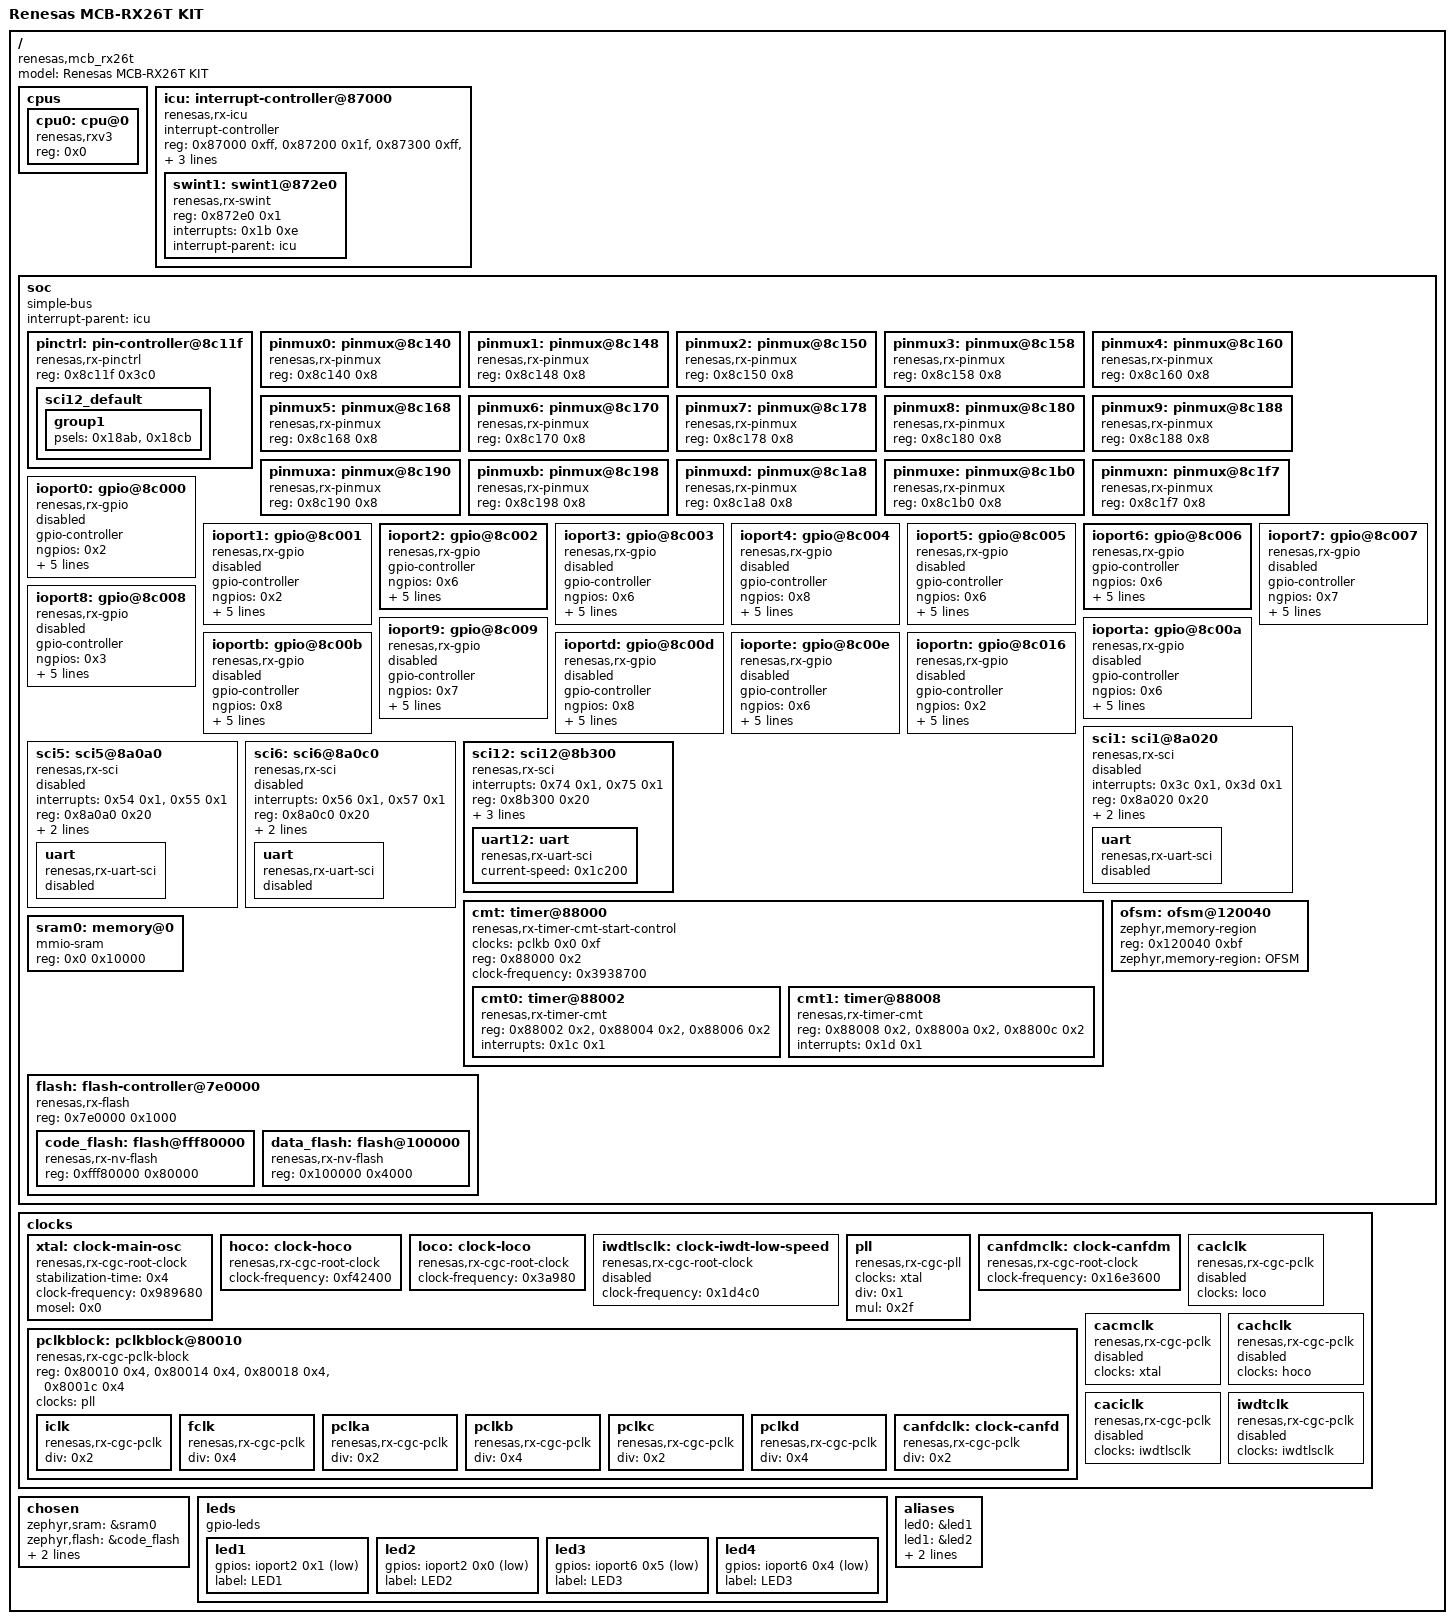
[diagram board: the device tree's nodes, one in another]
/dts-v1/;

/* node '/' defined in zephyr/dts/rx/renesas/rx26t-common.dtsi:15 */
/ {
	#address-cells = < 0x1 >;         /* in zephyr/dts/rx/renesas/rx26t-common.dtsi:16 */
	#size-cells = < 0x1 >;            /* in zephyr/dts/rx/renesas/rx26t-common.dtsi:17 */
	model = "Renesas MCB-RX26T KIT";  /* in zephyr/boards/renesas/mcb_rx26t/mcb_rx26t.dts:14 */
	compatible = "renesas,mcb_rx26t"; /* in zephyr/boards/renesas/mcb_rx26t/mcb_rx26t.dts:15 */

	/* node '/cpus' defined in zephyr/dts/rx/renesas/rx26t-common.dtsi:18 */
	cpus {
		#address-cells = < 0x1 >; /* in zephyr/dts/rx/renesas/rx26t-common.dtsi:19 */
		#size-cells = < 0x0 >;    /* in zephyr/dts/rx/renesas/rx26t-common.dtsi:20 */

		/* node '/cpus/cpu@0' defined in zephyr/dts/rx/renesas/rx26t-common.dtsi:22 */
		cpu0: cpu@0 {
			compatible = "renesas,rxv3"; /* in zephyr/dts/rx/renesas/rx26t-common.dtsi:23 */
			device_type = "cpu";         /* in zephyr/dts/rx/renesas/rx26t-common.dtsi:24 */
			reg = < 0x0 >;               /* in zephyr/dts/rx/renesas/rx26t-common.dtsi:25 */
			status = "okay";             /* in zephyr/dts/rx/renesas/rx26t-common.dtsi:26 */
		};
	};

	/* node '/interrupt-controller@87000' defined in zephyr/dts/rx/renesas/rx26t-common.dtsi:30 */
	icu: interrupt-controller@87000 {
		#interrupt-cells = < 0x2 >;    /* in zephyr/dts/rx/renesas/rx26t-common.dtsi:31 */
		#address-cells = < 0x1 >;      /* in zephyr/dts/rx/renesas/rx26t-common.dtsi:32 */
		#size-cells = < 0x1 >;         /* in zephyr/dts/rx/renesas/rx26t-common.dtsi:33 */
		compatible = "renesas,rx-icu"; /* in zephyr/dts/rx/renesas/rx26t-common.dtsi:34 */
		interrupt-controller;          /* in zephyr/dts/rx/renesas/rx26t-common.dtsi:35 */
		reg = < 0x87000 0xff >,
		      < 0x87200 0x1f >,
		      < 0x87300 0xff >,
		      < 0x872f0 0x2 >,
		      < 0x87500 0xf >,
		      < 0x87510 0x1 >,
		      < 0x87514 0x1 >,
		      < 0x87580 0x1 >,
		      < 0x87581 0x1 >,
		      < 0x87582 0x1 >;         /* in zephyr/dts/rx/renesas/rx26t-common.dtsi:36 */
		reg-names = "IR",
		            "IER",
		            "IPR",
		            "FIR",
		            "IRQCR",
		            "IRQFLTE",
		            "IRQFLTC0",
		            "NMISR",
		            "NMIER",
		            "NMICLR";          /* in zephyr/dts/rx/renesas/rx26t-common.dtsi:46 */
		phandle = < 0x1 >;             /* in zephyr/dts/rx/renesas/rx26t-common.dtsi:53 */

		/* node '/interrupt-controller@87000/swint1@872e0' defined in zephyr/dts/rx/renesas/rx26t-common.dtsi:49 */
		swint1: swint1@872e0 {
			compatible = "renesas,rx-swint"; /* in zephyr/dts/rx/renesas/rx26t-common.dtsi:50 */
			reg = < 0x872e0 0x1 >;           /* in zephyr/dts/rx/renesas/rx26t-common.dtsi:51 */
			interrupts = < 0x1b 0xe >;       /* in zephyr/dts/rx/renesas/rx26t-common.dtsi:52 */
			interrupt-parent = < &icu >;     /* in zephyr/dts/rx/renesas/rx26t-common.dtsi:53 */
			status = "okay";                 /* in zephyr/dts/rx/renesas/rx26t-common.dtsi:54 */
		};
	};

	/* node '/soc' defined in zephyr/dts/rx/renesas/rx26t-common.dtsi:58 */
	soc {
		#address-cells = < 0x1 >;    /* in zephyr/dts/rx/renesas/rx26t-common.dtsi:59 */
		#size-cells = < 0x1 >;       /* in zephyr/dts/rx/renesas/rx26t-common.dtsi:60 */
		device_type = "soc";         /* in zephyr/dts/rx/renesas/rx26t-common.dtsi:61 */
		compatible = "simple-bus";   /* in zephyr/dts/rx/renesas/rx26t-common.dtsi:62 */
		interrupt-parent = < &icu >; /* in zephyr/dts/rx/renesas/rx26t-common.dtsi:63 */

		/* node '/soc/pin-controller@8c11f' defined in zephyr/dts/rx/renesas/rx26t-common.dtsi:65 */
		pinctrl: pin-controller@8c11f {
			compatible = "renesas,rx-pinctrl"; /* in zephyr/dts/rx/renesas/rx26t-common.dtsi:66 */
			reg = < 0x8c11f 0x3c0 >;           /* in zephyr/dts/rx/renesas/rx26t-common.dtsi:67 */
			status = "okay";                   /* in zephyr/dts/rx/renesas/rx26t-common.dtsi:68 */

			/* node '/soc/pin-controller@8c11f/sci12_default' defined in zephyr/boards/renesas/mcb_rx26t/mcb_rx26t-pinctrl.dtsi:8 */
			sci12_default: sci12_default {
				phandle = < 0x11 >; /* in zephyr/boards/renesas/mcb_rx26t/mcb_rx26t.dts:83 */

				/* node '/soc/pin-controller@8c11f/sci12_default/group1' defined in zephyr/boards/renesas/mcb_rx26t/mcb_rx26t-pinctrl.dtsi:9 */
				group1 {
					psels = < 0x18ab >,
					        < 0x18cb >; /* in zephyr/boards/renesas/mcb_rx26t/mcb_rx26t-pinctrl.dtsi:10 */
				};
			};
		};

		/* node '/soc/pinmux@8c140' defined in zephyr/dts/rx/renesas/rx26t-common.dtsi:71 */
		pinmux0: pinmux@8c140 {
			compatible = "renesas,rx-pinmux"; /* in zephyr/dts/rx/renesas/rx26t-common.dtsi:72 */
			#pinmux-cells = < 0x2 >;          /* in zephyr/dts/rx/renesas/rx26t-common.dtsi:73 */
			reg = < 0x8c140 0x8 >;            /* in zephyr/dts/rx/renesas/rx26t-common.dtsi:74 */
			status = "okay";                  /* in zephyr/dts/rx/renesas/rx26t-common.dtsi:75 */
			phandle = < 0x2 >;                /* in zephyr/dts/rx/renesas/rx26t-common.dtsi:190 */
		};

		/* node '/soc/pinmux@8c148' defined in zephyr/dts/rx/renesas/rx26t-common.dtsi:78 */
		pinmux1: pinmux@8c148 {
			compatible = "renesas,rx-pinmux"; /* in zephyr/dts/rx/renesas/rx26t-common.dtsi:79 */
			#pinmux-cells = < 0x2 >;          /* in zephyr/dts/rx/renesas/rx26t-common.dtsi:80 */
			reg = < 0x8c148 0x8 >;            /* in zephyr/dts/rx/renesas/rx26t-common.dtsi:81 */
			status = "okay";                  /* in zephyr/dts/rx/renesas/rx26t-common.dtsi:82 */
			phandle = < 0x3 >;                /* in zephyr/dts/rx/renesas/rx26t-common.dtsi:208 */
		};

		/* node '/soc/pinmux@8c150' defined in zephyr/dts/rx/renesas/rx26t-common.dtsi:85 */
		pinmux2: pinmux@8c150 {
			compatible = "renesas,rx-pinmux"; /* in zephyr/dts/rx/renesas/rx26t-common.dtsi:86 */
			#pinmux-cells = < 0x2 >;          /* in zephyr/dts/rx/renesas/rx26t-common.dtsi:87 */
			reg = < 0x8c150 0x8 >;            /* in zephyr/dts/rx/renesas/rx26t-common.dtsi:88 */
			status = "okay";                  /* in zephyr/dts/rx/renesas/rx26t-common.dtsi:89 */
			phandle = < 0x4 >;                /* in zephyr/dts/rx/renesas/rx26t-common.dtsi:227 */
		};

		/* node '/soc/pinmux@8c158' defined in zephyr/dts/rx/renesas/rx26t-common.dtsi:92 */
		pinmux3: pinmux@8c158 {
			compatible = "renesas,rx-pinmux"; /* in zephyr/dts/rx/renesas/rx26t-common.dtsi:93 */
			#pinmux-cells = < 0x2 >;          /* in zephyr/dts/rx/renesas/rx26t-common.dtsi:94 */
			reg = < 0x8c158 0x8 >;            /* in zephyr/dts/rx/renesas/rx26t-common.dtsi:95 */
			status = "okay";                  /* in zephyr/dts/rx/renesas/rx26t-common.dtsi:96 */
			phandle = < 0x5 >;                /* in zephyr/dts/rx/renesas/rx26t-common.dtsi:246 */
		};

		/* node '/soc/pinmux@8c160' defined in zephyr/dts/rx/renesas/rx26t-common.dtsi:99 */
		pinmux4: pinmux@8c160 {
			compatible = "renesas,rx-pinmux"; /* in zephyr/dts/rx/renesas/rx26t-common.dtsi:100 */
			#pinmux-cells = < 0x2 >;          /* in zephyr/dts/rx/renesas/rx26t-common.dtsi:101 */
			reg = < 0x8c160 0x8 >;            /* in zephyr/dts/rx/renesas/rx26t-common.dtsi:102 */
			status = "okay";                  /* in zephyr/dts/rx/renesas/rx26t-common.dtsi:103 */
			phandle = < 0x6 >;                /* in zephyr/dts/rx/renesas/rx26t-common.dtsi:264 */
		};

		/* node '/soc/pinmux@8c168' defined in zephyr/dts/rx/renesas/rx26t-common.dtsi:106 */
		pinmux5: pinmux@8c168 {
			compatible = "renesas,rx-pinmux"; /* in zephyr/dts/rx/renesas/rx26t-common.dtsi:107 */
			#pinmux-cells = < 0x2 >;          /* in zephyr/dts/rx/renesas/rx26t-common.dtsi:108 */
			reg = < 0x8c168 0x8 >;            /* in zephyr/dts/rx/renesas/rx26t-common.dtsi:109 */
			status = "okay";                  /* in zephyr/dts/rx/renesas/rx26t-common.dtsi:110 */
			phandle = < 0x7 >;                /* in zephyr/dts/rx/renesas/rx26t-common.dtsi:282 */
		};

		/* node '/soc/pinmux@8c170' defined in zephyr/dts/rx/renesas/rx26t-common.dtsi:113 */
		pinmux6: pinmux@8c170 {
			compatible = "renesas,rx-pinmux"; /* in zephyr/dts/rx/renesas/rx26t-common.dtsi:114 */
			#pinmux-cells = < 0x2 >;          /* in zephyr/dts/rx/renesas/rx26t-common.dtsi:115 */
			reg = < 0x8c170 0x8 >;            /* in zephyr/dts/rx/renesas/rx26t-common.dtsi:116 */
			status = "okay";                  /* in zephyr/dts/rx/renesas/rx26t-common.dtsi:117 */
		};

		/* node '/soc/pinmux@8c178' defined in zephyr/dts/rx/renesas/rx26t-common.dtsi:120 */
		pinmux7: pinmux@8c178 {
			compatible = "renesas,rx-pinmux"; /* in zephyr/dts/rx/renesas/rx26t-common.dtsi:121 */
			#pinmux-cells = < 0x2 >;          /* in zephyr/dts/rx/renesas/rx26t-common.dtsi:122 */
			reg = < 0x8c178 0x8 >;            /* in zephyr/dts/rx/renesas/rx26t-common.dtsi:123 */
			status = "okay";                  /* in zephyr/dts/rx/renesas/rx26t-common.dtsi:124 */
			phandle = < 0x8 >;                /* in zephyr/dts/rx/renesas/rx26t-common.dtsi:321 */
		};

		/* node '/soc/pinmux@8c180' defined in zephyr/dts/rx/renesas/rx26t-common.dtsi:127 */
		pinmux8: pinmux@8c180 {
			compatible = "renesas,rx-pinmux"; /* in zephyr/dts/rx/renesas/rx26t-common.dtsi:128 */
			#pinmux-cells = < 0x2 >;          /* in zephyr/dts/rx/renesas/rx26t-common.dtsi:129 */
			reg = < 0x8c180 0x8 >;            /* in zephyr/dts/rx/renesas/rx26t-common.dtsi:130 */
			status = "okay";                  /* in zephyr/dts/rx/renesas/rx26t-common.dtsi:131 */
			phandle = < 0x9 >;                /* in zephyr/dts/rx/renesas/rx26t-common.dtsi:341 */
		};

		/* node '/soc/pinmux@8c188' defined in zephyr/dts/rx/renesas/rx26t-common.dtsi:134 */
		pinmux9: pinmux@8c188 {
			compatible = "renesas,rx-pinmux"; /* in zephyr/dts/rx/renesas/rx26t-common.dtsi:135 */
			#pinmux-cells = < 0x2 >;          /* in zephyr/dts/rx/renesas/rx26t-common.dtsi:136 */
			reg = < 0x8c188 0x8 >;            /* in zephyr/dts/rx/renesas/rx26t-common.dtsi:137 */
			status = "okay";                  /* in zephyr/dts/rx/renesas/rx26t-common.dtsi:138 */
			phandle = < 0xa >;                /* in zephyr/dts/rx/renesas/rx26t-common.dtsi:362 */
		};

		/* node '/soc/pinmux@8c190' defined in zephyr/dts/rx/renesas/rx26t-common.dtsi:141 */
		pinmuxa: pinmux@8c190 {
			compatible = "renesas,rx-pinmux"; /* in zephyr/dts/rx/renesas/rx26t-common.dtsi:142 */
			#pinmux-cells = < 0x2 >;          /* in zephyr/dts/rx/renesas/rx26t-common.dtsi:143 */
			reg = < 0x8c190 0x8 >;            /* in zephyr/dts/rx/renesas/rx26t-common.dtsi:144 */
			status = "okay";                  /* in zephyr/dts/rx/renesas/rx26t-common.dtsi:145 */
			phandle = < 0xb >;                /* in zephyr/dts/rx/renesas/rx26t-common.dtsi:382 */
		};

		/* node '/soc/pinmux@8c198' defined in zephyr/dts/rx/renesas/rx26t-common.dtsi:148 */
		pinmuxb: pinmux@8c198 {
			compatible = "renesas,rx-pinmux"; /* in zephyr/dts/rx/renesas/rx26t-common.dtsi:149 */
			#pinmux-cells = < 0x2 >;          /* in zephyr/dts/rx/renesas/rx26t-common.dtsi:150 */
			reg = < 0x8c198 0x8 >;            /* in zephyr/dts/rx/renesas/rx26t-common.dtsi:151 */
			status = "okay";                  /* in zephyr/dts/rx/renesas/rx26t-common.dtsi:152 */
			phandle = < 0xc >;                /* in zephyr/dts/rx/renesas/rx26t-common.dtsi:403 */
		};

		/* node '/soc/pinmux@8c1a8' defined in zephyr/dts/rx/renesas/rx26t-common.dtsi:155 */
		pinmuxd: pinmux@8c1a8 {
			compatible = "renesas,rx-pinmux"; /* in zephyr/dts/rx/renesas/rx26t-common.dtsi:156 */
			#pinmux-cells = < 0x2 >;          /* in zephyr/dts/rx/renesas/rx26t-common.dtsi:157 */
			reg = < 0x8c1a8 0x8 >;            /* in zephyr/dts/rx/renesas/rx26t-common.dtsi:158 */
			status = "okay";                  /* in zephyr/dts/rx/renesas/rx26t-common.dtsi:159 */
			phandle = < 0xd >;                /* in zephyr/dts/rx/renesas/rx26t-common.dtsi:424 */
		};

		/* node '/soc/pinmux@8c1b0' defined in zephyr/dts/rx/renesas/rx26t-common.dtsi:162 */
		pinmuxe: pinmux@8c1b0 {
			compatible = "renesas,rx-pinmux"; /* in zephyr/dts/rx/renesas/rx26t-common.dtsi:163 */
			#pinmux-cells = < 0x2 >;          /* in zephyr/dts/rx/renesas/rx26t-common.dtsi:164 */
			reg = < 0x8c1b0 0x8 >;            /* in zephyr/dts/rx/renesas/rx26t-common.dtsi:165 */
			status = "okay";                  /* in zephyr/dts/rx/renesas/rx26t-common.dtsi:166 */
			phandle = < 0xe >;                /* in zephyr/dts/rx/renesas/rx26t-common.dtsi:443 */
		};

		/* node '/soc/pinmux@8c1f7' defined in zephyr/dts/rx/renesas/rx26t-common.dtsi:169 */
		pinmuxn: pinmux@8c1f7 {
			compatible = "renesas,rx-pinmux"; /* in zephyr/dts/rx/renesas/rx26t-common.dtsi:170 */
			#pinmux-cells = < 0x2 >;          /* in zephyr/dts/rx/renesas/rx26t-common.dtsi:171 */
			reg = < 0x8c1f7 0x8 >;            /* in zephyr/dts/rx/renesas/rx26t-common.dtsi:172 */
			status = "okay";                  /* in zephyr/dts/rx/renesas/rx26t-common.dtsi:173 */
			phandle = < 0xf >;                /* in zephyr/dts/rx/renesas/rx26t-common.dtsi:461 */
		};

		/* node '/soc/gpio@8c000' defined in zephyr/dts/rx/renesas/rx26t-common.dtsi:176 */
		ioport0: gpio@8c000 {
			compatible = "renesas,rx-gpio"; /* in zephyr/dts/rx/renesas/rx26t-common.dtsi:177 */
			gpio-controller;                /* in zephyr/dts/rx/renesas/rx26t-common.dtsi:178 */
			#gpio-cells = < 0x2 >;          /* in zephyr/dts/rx/renesas/rx26t-common.dtsi:179 */
			ngpios = < 0x2 >;               /* in zephyr/dts/rx/renesas/rx26t-common.dtsi:180 */
			port = < 0x0 >;                 /* in zephyr/dts/rx/renesas/rx26t-common.dtsi:181 */
			reg = < 0x8c000 0x1 >,
			      < 0x8c020 0x1 >,
			      < 0x8c040 0x1 >,
			      < 0x8c060 0x1 >,
			      < 0x8c080 0x1 >,
			      < 0x8c0c0 0x1 >,
			      < 0x8c0e0 0x1 >;          /* in zephyr/dts/rx/renesas/rx26t-common.dtsi:182 */
			reg-names = "PDR",
			            "PODR",
			            "PIDR",
			            "PMR",
			            "ODR0",
			            "PCR",
			            "DSCR";             /* in zephyr/dts/rx/renesas/rx26t-common.dtsi:189 */
			pinmux = < &pinmux0 >;          /* in zephyr/dts/rx/renesas/rx26t-common.dtsi:190 */
			status = "disabled";            /* in zephyr/dts/rx/renesas/rx26t-common.dtsi:191 */
		};

		/* node '/soc/gpio@8c001' defined in zephyr/dts/rx/renesas/rx26t-common.dtsi:194 */
		ioport1: gpio@8c001 {
			compatible = "renesas,rx-gpio"; /* in zephyr/dts/rx/renesas/rx26t-common.dtsi:195 */
			gpio-controller;                /* in zephyr/dts/rx/renesas/rx26t-common.dtsi:196 */
			#gpio-cells = < 0x2 >;          /* in zephyr/dts/rx/renesas/rx26t-common.dtsi:197 */
			ngpios = < 0x2 >;               /* in zephyr/dts/rx/renesas/rx26t-common.dtsi:198 */
			port = < 0x1 >;                 /* in zephyr/dts/rx/renesas/rx26t-common.dtsi:199 */
			reg = < 0x8c001 0x1 >,
			      < 0x8c021 0x1 >,
			      < 0x8c041 0x1 >,
			      < 0x8c061 0x1 >,
			      < 0x8c082 0x1 >,
			      < 0x8c0c1 0x1 >,
			      < 0x8c0e1 0x1 >;          /* in zephyr/dts/rx/renesas/rx26t-common.dtsi:200 */
			reg-names = "PDR",
			            "PODR",
			            "PIDR",
			            "PMR",
			            "ODR0",
			            "PCR",
			            "DSCR";             /* in zephyr/dts/rx/renesas/rx26t-common.dtsi:207 */
			pinmux = < &pinmux1 >;          /* in zephyr/dts/rx/renesas/rx26t-common.dtsi:208 */
			status = "disabled";            /* in zephyr/dts/rx/renesas/rx26t-common.dtsi:209 */
		};

		/* node '/soc/gpio@8c002' defined in zephyr/dts/rx/renesas/rx26t-common.dtsi:212 */
		ioport2: gpio@8c002 {
			compatible = "renesas,rx-gpio"; /* in zephyr/dts/rx/renesas/rx26t-common.dtsi:213 */
			gpio-controller;                /* in zephyr/dts/rx/renesas/rx26t-common.dtsi:214 */
			#gpio-cells = < 0x2 >;          /* in zephyr/dts/rx/renesas/rx26t-common.dtsi:215 */
			ngpios = < 0x6 >;               /* in zephyr/dts/rx/renesas/rx26t-common.dtsi:216 */
			port = < 0x2 >;                 /* in zephyr/dts/rx/renesas/rx26t-common.dtsi:217 */
			reg = < 0x8c002 0x1 >,
			      < 0x8c022 0x1 >,
			      < 0x8c042 0x1 >,
			      < 0x8c062 0x1 >,
			      < 0x8c084 0x1 >,
			      < 0x8c085 0x1 >,
			      < 0x8c0c2 0x1 >,
			      < 0x8c0e2 0x1 >;          /* in zephyr/dts/rx/renesas/rx26t-common.dtsi:218 */
			reg-names = "PDR",
			            "PODR",
			            "PIDR",
			            "PMR",
			            "ODR0",
			            "ODR1",
			            "PCR",
			            "DSCR";             /* in zephyr/dts/rx/renesas/rx26t-common.dtsi:226 */
			pinmux = < &pinmux2 >;          /* in zephyr/dts/rx/renesas/rx26t-common.dtsi:227 */
			status = "okay";                /* in zephyr/boards/renesas/mcb_rx26t/mcb_rx26t.dts:75 */
			phandle = < 0x17 >;             /* in zephyr/boards/renesas/mcb_rx26t/mcb_rx26t.dts:28 */
		};

		/* node '/soc/gpio@8c003' defined in zephyr/dts/rx/renesas/rx26t-common.dtsi:231 */
		ioport3: gpio@8c003 {
			compatible = "renesas,rx-gpio"; /* in zephyr/dts/rx/renesas/rx26t-common.dtsi:232 */
			gpio-controller;                /* in zephyr/dts/rx/renesas/rx26t-common.dtsi:233 */
			#gpio-cells = < 0x2 >;          /* in zephyr/dts/rx/renesas/rx26t-common.dtsi:234 */
			ngpios = < 0x6 >;               /* in zephyr/dts/rx/renesas/rx26t-common.dtsi:235 */
			port = < 0x3 >;                 /* in zephyr/dts/rx/renesas/rx26t-common.dtsi:236 */
			reg = < 0x8c003 0x1 >,
			      < 0x8c023 0x1 >,
			      < 0x8c043 0x1 >,
			      < 0x8c063 0x1 >,
			      < 0x8c086 0x1 >,
			      < 0x8c087 0x1 >,
			      < 0x8c0c3 0x1 >,
			      < 0x8c0e3 0x1 >;          /* in zephyr/dts/rx/renesas/rx26t-common.dtsi:237 */
			reg-names = "PDR",
			            "PODR",
			            "PIDR",
			            "PMR",
			            "ODR0",
			            "ODR1",
			            "PCR",
			            "DSCR";             /* in zephyr/dts/rx/renesas/rx26t-common.dtsi:245 */
			pinmux = < &pinmux3 >;          /* in zephyr/dts/rx/renesas/rx26t-common.dtsi:246 */
			status = "disabled";            /* in zephyr/dts/rx/renesas/rx26t-common.dtsi:247 */
		};

		/* node '/soc/gpio@8c004' defined in zephyr/dts/rx/renesas/rx26t-common.dtsi:250 */
		ioport4: gpio@8c004 {
			compatible = "renesas,rx-gpio"; /* in zephyr/dts/rx/renesas/rx26t-common.dtsi:251 */
			gpio-controller;                /* in zephyr/dts/rx/renesas/rx26t-common.dtsi:252 */
			#gpio-cells = < 0x2 >;          /* in zephyr/dts/rx/renesas/rx26t-common.dtsi:253 */
			ngpios = < 0x8 >;               /* in zephyr/dts/rx/renesas/rx26t-common.dtsi:254 */
			port = < 0x4 >;                 /* in zephyr/dts/rx/renesas/rx26t-common.dtsi:255 */
			reg = < 0x8c004 0x1 >,
			      < 0x8c024 0x1 >,
			      < 0x8c044 0x1 >,
			      < 0x8c064 0x1 >,
			      < 0x8c088 0x1 >,
			      < 0x8c089 0x1 >,
			      < 0x8c0c4 0x1 >;          /* in zephyr/dts/rx/renesas/rx26t-common.dtsi:256 */
			reg-names = "PDR",
			            "PODR",
			            "PIDR",
			            "PMR",
			            "ODR0",
			            "ODR1",
			            "PCR";              /* in zephyr/dts/rx/renesas/rx26t-common.dtsi:263 */
			pinmux = < &pinmux4 >;          /* in zephyr/dts/rx/renesas/rx26t-common.dtsi:264 */
			status = "disabled";            /* in zephyr/dts/rx/renesas/rx26t-common.dtsi:265 */
		};

		/* node '/soc/gpio@8c005' defined in zephyr/dts/rx/renesas/rx26t-common.dtsi:268 */
		ioport5: gpio@8c005 {
			compatible = "renesas,rx-gpio"; /* in zephyr/dts/rx/renesas/rx26t-common.dtsi:269 */
			gpio-controller;                /* in zephyr/dts/rx/renesas/rx26t-common.dtsi:270 */
			#gpio-cells = < 0x2 >;          /* in zephyr/dts/rx/renesas/rx26t-common.dtsi:271 */
			ngpios = < 0x6 >;               /* in zephyr/dts/rx/renesas/rx26t-common.dtsi:272 */
			port = < 0x5 >;                 /* in zephyr/dts/rx/renesas/rx26t-common.dtsi:273 */
			reg = < 0x8c005 0x1 >,
			      < 0x8c025 0x1 >,
			      < 0x8c045 0x1 >,
			      < 0x8c065 0x1 >,
			      < 0x8c08a 0x1 >,
			      < 0x8c08b 0x1 >,
			      < 0x8c0c5 0x1 >;          /* in zephyr/dts/rx/renesas/rx26t-common.dtsi:274 */
			reg-names = "PDR",
			            "PODR",
			            "PIDR",
			            "PMR",
			            "ODR0",
			            "ODR1",
			            "PCR";              /* in zephyr/dts/rx/renesas/rx26t-common.dtsi:281 */
			pinmux = < &pinmux5 >;          /* in zephyr/dts/rx/renesas/rx26t-common.dtsi:282 */
			status = "disabled";            /* in zephyr/dts/rx/renesas/rx26t-common.dtsi:283 */
		};

		/* node '/soc/gpio@8c006' defined in zephyr/dts/rx/renesas/rx26t-common.dtsi:286 */
		ioport6: gpio@8c006 {
			compatible = "renesas,rx-gpio"; /* in zephyr/dts/rx/renesas/rx26t-common.dtsi:287 */
			gpio-controller;                /* in zephyr/dts/rx/renesas/rx26t-common.dtsi:288 */
			#gpio-cells = < 0x2 >;          /* in zephyr/dts/rx/renesas/rx26t-common.dtsi:289 */
			ngpios = < 0x6 >;               /* in zephyr/dts/rx/renesas/rx26t-common.dtsi:290 */
			port = < 0x6 >;                 /* in zephyr/dts/rx/renesas/rx26t-common.dtsi:291 */
			reg = < 0x8c006 0x1 >,
			      < 0x8c026 0x1 >,
			      < 0x8c046 0x1 >,
			      < 0x8c066 0x1 >,
			      < 0x8c08c 0x1 >,
			      < 0x8c08d 0x1 >,
			      < 0x8c0c6 0x1 >;          /* in zephyr/dts/rx/renesas/rx26t-common.dtsi:292 */
			reg-names = "PDR",
			            "PODR",
			            "PIDR",
			            "PMR",
			            "ODR0",
			            "ODR1",
			            "PCR";              /* in zephyr/dts/rx/renesas/rx26t-common.dtsi:299 */
			pinmux = < &pinmux5 >;          /* in zephyr/dts/rx/renesas/rx26t-common.dtsi:300 */
			status = "okay";                /* in zephyr/boards/renesas/mcb_rx26t/mcb_rx26t.dts:79 */
			phandle = < 0x18 >;             /* in zephyr/boards/renesas/mcb_rx26t/mcb_rx26t.dts:38 */
		};

		/* node '/soc/gpio@8c007' defined in zephyr/dts/rx/renesas/rx26t-common.dtsi:304 */
		ioport7: gpio@8c007 {
			compatible = "renesas,rx-gpio"; /* in zephyr/dts/rx/renesas/rx26t-common.dtsi:305 */
			gpio-controller;                /* in zephyr/dts/rx/renesas/rx26t-common.dtsi:306 */
			#gpio-cells = < 0x2 >;          /* in zephyr/dts/rx/renesas/rx26t-common.dtsi:307 */
			ngpios = < 0x7 >;               /* in zephyr/dts/rx/renesas/rx26t-common.dtsi:308 */
			port = < 0x7 >;                 /* in zephyr/dts/rx/renesas/rx26t-common.dtsi:309 */
			reg = < 0x8c007 0x1 >,
			      < 0x8c027 0x1 >,
			      < 0x8c047 0x1 >,
			      < 0x8c067 0x1 >,
			      < 0x8c08e 0x1 >,
			      < 0x8c08f 0x1 >,
			      < 0x8c0c7 0x1 >,
			      < 0x8c0e7 0x1 >,
			      < 0x8c12f 0x1 >;          /* in zephyr/dts/rx/renesas/rx26t-common.dtsi:310 */
			reg-names = "PDR",
			            "PODR",
			            "PIDR",
			            "PMR",
			            "ODR0",
			            "ODR1",
			            "PCR",
			            "DSCR",
			            "DSCR2";            /* in zephyr/dts/rx/renesas/rx26t-common.dtsi:319 */
			pinmux = < &pinmux7 >;          /* in zephyr/dts/rx/renesas/rx26t-common.dtsi:321 */
			status = "disabled";            /* in zephyr/dts/rx/renesas/rx26t-common.dtsi:322 */
		};

		/* node '/soc/gpio@8c008' defined in zephyr/dts/rx/renesas/rx26t-common.dtsi:325 */
		ioport8: gpio@8c008 {
			compatible = "renesas,rx-gpio"; /* in zephyr/dts/rx/renesas/rx26t-common.dtsi:326 */
			gpio-controller;                /* in zephyr/dts/rx/renesas/rx26t-common.dtsi:327 */
			#gpio-cells = < 0x2 >;          /* in zephyr/dts/rx/renesas/rx26t-common.dtsi:328 */
			ngpios = < 0x3 >;               /* in zephyr/dts/rx/renesas/rx26t-common.dtsi:329 */
			port = < 0x8 >;                 /* in zephyr/dts/rx/renesas/rx26t-common.dtsi:330 */
			reg = < 0x8c008 0x1 >,
			      < 0x8c028 0x1 >,
			      < 0x8c048 0x1 >,
			      < 0x8c068 0x1 >,
			      < 0x8c090 0x1 >,
			      < 0x8c0c8 0x1 >,
			      < 0x8c0e8 0x1 >,
			      < 0x8c130 0x1 >;          /* in zephyr/dts/rx/renesas/rx26t-common.dtsi:331 */
			reg-names = "PDR",
			            "PODR",
			            "PIDR",
			            "PMR",
			            "ODR0",
			            "PCR",
			            "DSCR",
			            "DSCR2";            /* in zephyr/dts/rx/renesas/rx26t-common.dtsi:339 */
			pinmux = < &pinmux8 >;          /* in zephyr/dts/rx/renesas/rx26t-common.dtsi:341 */
			status = "disabled";            /* in zephyr/dts/rx/renesas/rx26t-common.dtsi:342 */
		};

		/* node '/soc/gpio@8c009' defined in zephyr/dts/rx/renesas/rx26t-common.dtsi:345 */
		ioport9: gpio@8c009 {
			compatible = "renesas,rx-gpio"; /* in zephyr/dts/rx/renesas/rx26t-common.dtsi:346 */
			gpio-controller;                /* in zephyr/dts/rx/renesas/rx26t-common.dtsi:347 */
			#gpio-cells = < 0x2 >;          /* in zephyr/dts/rx/renesas/rx26t-common.dtsi:348 */
			ngpios = < 0x7 >;               /* in zephyr/dts/rx/renesas/rx26t-common.dtsi:349 */
			port = < 0x9 >;                 /* in zephyr/dts/rx/renesas/rx26t-common.dtsi:350 */
			reg = < 0x8c009 0x1 >,
			      < 0x8c029 0x1 >,
			      < 0x8c049 0x1 >,
			      < 0x8c069 0x1 >,
			      < 0x8c092 0x1 >,
			      < 0x8c093 0x1 >,
			      < 0x8c0c9 0x1 >,
			      < 0x8c0e9 0x1 >,
			      < 0x8c131 0x1 >;          /* in zephyr/dts/rx/renesas/rx26t-common.dtsi:351 */
			reg-names = "PDR",
			            "PODR",
			            "PIDR",
			            "PMR",
			            "ODR0",
			            "ODR1",
			            "PCR",
			            "DSCR",
			            "DSCR2";            /* in zephyr/dts/rx/renesas/rx26t-common.dtsi:360 */
			pinmux = < &pinmux9 >;          /* in zephyr/dts/rx/renesas/rx26t-common.dtsi:362 */
			status = "disabled";            /* in zephyr/dts/rx/renesas/rx26t-common.dtsi:363 */
		};

		/* node '/soc/gpio@8c00a' defined in zephyr/dts/rx/renesas/rx26t-common.dtsi:366 */
		ioporta: gpio@8c00a {
			compatible = "renesas,rx-gpio"; /* in zephyr/dts/rx/renesas/rx26t-common.dtsi:367 */
			gpio-controller;                /* in zephyr/dts/rx/renesas/rx26t-common.dtsi:368 */
			#gpio-cells = < 0x2 >;          /* in zephyr/dts/rx/renesas/rx26t-common.dtsi:369 */
			ngpios = < 0x6 >;               /* in zephyr/dts/rx/renesas/rx26t-common.dtsi:370 */
			port = < 0xa >;                 /* in zephyr/dts/rx/renesas/rx26t-common.dtsi:371 */
			reg = < 0x8c00a 0x1 >,
			      < 0x8c02a 0x1 >,
			      < 0x8c04a 0x1 >,
			      < 0x8c06a 0x1 >,
			      < 0x8c094 0x1 >,
			      < 0x8c095 0x1 >,
			      < 0x8c0ca 0x1 >,
			      < 0x8c0ea 0x1 >;          /* in zephyr/dts/rx/renesas/rx26t-common.dtsi:372 */
			reg-names = "PDR",
			            "PODR",
			            "PIDR",
			            "PMR",
			            "ODR0",
			            "ODR1",
			            "PCR",
			            "DSCR";             /* in zephyr/dts/rx/renesas/rx26t-common.dtsi:380 */
			pinmux = < &pinmuxa >;          /* in zephyr/dts/rx/renesas/rx26t-common.dtsi:382 */
			status = "disabled";            /* in zephyr/dts/rx/renesas/rx26t-common.dtsi:383 */
		};

		/* node '/soc/gpio@8c00b' defined in zephyr/dts/rx/renesas/rx26t-common.dtsi:386 */
		ioportb: gpio@8c00b {
			compatible = "renesas,rx-gpio"; /* in zephyr/dts/rx/renesas/rx26t-common.dtsi:387 */
			gpio-controller;                /* in zephyr/dts/rx/renesas/rx26t-common.dtsi:388 */
			#gpio-cells = < 0x2 >;          /* in zephyr/dts/rx/renesas/rx26t-common.dtsi:389 */
			ngpios = < 0x8 >;               /* in zephyr/dts/rx/renesas/rx26t-common.dtsi:390 */
			port = < 0xb >;                 /* in zephyr/dts/rx/renesas/rx26t-common.dtsi:391 */
			reg = < 0x8c00b 0x1 >,
			      < 0x8c02b 0x1 >,
			      < 0x8c04b 0x1 >,
			      < 0x8c06b 0x1 >,
			      < 0x8c096 0x1 >,
			      < 0x8c097 0x1 >,
			      < 0x8c0cb 0x1 >,
			      < 0x8c0eb 0x1 >,
			      < 0x8c133 0x1 >;          /* in zephyr/dts/rx/renesas/rx26t-common.dtsi:392 */
			reg-names = "PDR",
			            "PODR",
			            "PIDR",
			            "PMR",
			            "ODR0",
			            "ODR1",
			            "PCR",
			            "DSCR",
			            "DSCR2";            /* in zephyr/dts/rx/renesas/rx26t-common.dtsi:401 */
			pinmux = < &pinmuxb >;          /* in zephyr/dts/rx/renesas/rx26t-common.dtsi:403 */
			status = "disabled";            /* in zephyr/dts/rx/renesas/rx26t-common.dtsi:404 */
		};

		/* node '/soc/gpio@8c00d' defined in zephyr/dts/rx/renesas/rx26t-common.dtsi:407 */
		ioportd: gpio@8c00d {
			compatible = "renesas,rx-gpio"; /* in zephyr/dts/rx/renesas/rx26t-common.dtsi:408 */
			gpio-controller;                /* in zephyr/dts/rx/renesas/rx26t-common.dtsi:409 */
			#gpio-cells = < 0x2 >;          /* in zephyr/dts/rx/renesas/rx26t-common.dtsi:410 */
			ngpios = < 0x8 >;               /* in zephyr/dts/rx/renesas/rx26t-common.dtsi:411 */
			port = < 0xd >;                 /* in zephyr/dts/rx/renesas/rx26t-common.dtsi:412 */
			reg = < 0x8c00d 0x1 >,
			      < 0x8c02d 0x1 >,
			      < 0x8c04d 0x1 >,
			      < 0x8c06d 0x1 >,
			      < 0x8c09a 0x1 >,
			      < 0x8c09b 0x1 >,
			      < 0x8c0cd 0x1 >,
			      < 0x8c0ed 0x1 >,
			      < 0x8c135 0x1 >;          /* in zephyr/dts/rx/renesas/rx26t-common.dtsi:413 */
			reg-names = "PDR",
			            "PODR",
			            "PIDR",
			            "PMR",
			            "ODR0",
			            "ODR1",
			            "PCR",
			            "DSCR",
			            "DSCR2";            /* in zephyr/dts/rx/renesas/rx26t-common.dtsi:422 */
			pinmux = < &pinmuxd >;          /* in zephyr/dts/rx/renesas/rx26t-common.dtsi:424 */
			status = "disabled";            /* in zephyr/dts/rx/renesas/rx26t-common.dtsi:425 */
		};

		/* node '/soc/gpio@8c00e' defined in zephyr/dts/rx/renesas/rx26t-common.dtsi:428 */
		ioporte: gpio@8c00e {
			compatible = "renesas,rx-gpio"; /* in zephyr/dts/rx/renesas/rx26t-common.dtsi:429 */
			gpio-controller;                /* in zephyr/dts/rx/renesas/rx26t-common.dtsi:430 */
			#gpio-cells = < 0x2 >;          /* in zephyr/dts/rx/renesas/rx26t-common.dtsi:431 */
			ngpios = < 0x6 >;               /* in zephyr/dts/rx/renesas/rx26t-common.dtsi:432 */
			port = < 0xe >;                 /* in zephyr/dts/rx/renesas/rx26t-common.dtsi:433 */
			reg = < 0x8c00e 0x1 >,
			      < 0x8c02e 0x1 >,
			      < 0x8c04e 0x1 >,
			      < 0x8c06e 0x1 >,
			      < 0x8c09c 0x1 >,
			      < 0x8c09d 0x1 >,
			      < 0x8c0ce 0x1 >,
			      < 0x8c0ee 0x1 >;          /* in zephyr/dts/rx/renesas/rx26t-common.dtsi:434 */
			reg-names = "PDR",
			            "PODR",
			            "PIDR",
			            "PMR",
			            "ODR0",
			            "ODR1",
			            "PCR",
			            "DSCR";             /* in zephyr/dts/rx/renesas/rx26t-common.dtsi:442 */
			pinmux = < &pinmuxe >;          /* in zephyr/dts/rx/renesas/rx26t-common.dtsi:443 */
			status = "disabled";            /* in zephyr/dts/rx/renesas/rx26t-common.dtsi:444 */
		};

		/* node '/soc/gpio@8c016' defined in zephyr/dts/rx/renesas/rx26t-common.dtsi:447 */
		ioportn: gpio@8c016 {
			compatible = "renesas,rx-gpio"; /* in zephyr/dts/rx/renesas/rx26t-common.dtsi:448 */
			gpio-controller;                /* in zephyr/dts/rx/renesas/rx26t-common.dtsi:449 */
			#gpio-cells = < 0x2 >;          /* in zephyr/dts/rx/renesas/rx26t-common.dtsi:450 */
			ngpios = < 0x2 >;               /* in zephyr/dts/rx/renesas/rx26t-common.dtsi:451 */
			port = < 0x17 >;                /* in zephyr/dts/rx/renesas/rx26t-common.dtsi:452 */
			reg = < 0x8c016 0x1 >,
			      < 0x8c036 0x1 >,
			      < 0x8c056 0x1 >,
			      < 0x8c076 0x1 >,
			      < 0x8c0d6 0x1 >,
			      < 0x8c0f6 0x1 >,
			      < 0x8c0ad 0x1 >;          /* in zephyr/dts/rx/renesas/rx26t-common.dtsi:453 */
			reg-names = "PDR",
			            "PODR",
			            "PIDR",
			            "PMR",
			            "PCR",
			            "DSCR",
			            "ODR1";             /* in zephyr/dts/rx/renesas/rx26t-common.dtsi:460 */
			pinmux = < &pinmuxn >;          /* in zephyr/dts/rx/renesas/rx26t-common.dtsi:461 */
			status = "disabled";            /* in zephyr/dts/rx/renesas/rx26t-common.dtsi:462 */
		};

		/* node '/soc/sci1@8a020' defined in zephyr/dts/rx/renesas/rx26t-common.dtsi:465 */
		sci1: sci1@8a020 {
			compatible = "renesas,rx-sci"; /* in zephyr/dts/rx/renesas/rx26t-common.dtsi:466 */
			interrupts = < 0x3c 0x1 >,
			             < 0x3d 0x1 >;     /* in zephyr/dts/rx/renesas/rx26t-common.dtsi:467 */
			interrupt-names = "rxi",
			                  "txi";       /* in zephyr/dts/rx/renesas/rx26t-common.dtsi:468 */
			reg = < 0x8a020 0x20 >;        /* in zephyr/dts/rx/renesas/rx26t-common.dtsi:469 */
			clocks = < &pclkb 0x1 0x1e >;  /* in zephyr/dts/rx/renesas/rx26t-common.dtsi:470 */
			status = "disabled";           /* in zephyr/dts/rx/renesas/rx26t-common.dtsi:471 */
			channel = < 0x1 >;             /* in zephyr/dts/rx/renesas/rx26t-common.dtsi:472 */

			/* node '/soc/sci1@8a020/uart' defined in zephyr/dts/rx/renesas/rx26t-common.dtsi:474 */
			uart {
				compatible = "renesas,rx-uart-sci"; /* in zephyr/dts/rx/renesas/rx26t-common.dtsi:475 */
				status = "disabled";                /* in zephyr/dts/rx/renesas/rx26t-common.dtsi:476 */
			};
		};

		/* node '/soc/sci5@8a0a0' defined in zephyr/dts/rx/renesas/rx26t-common.dtsi:480 */
		sci5: sci5@8a0a0 {
			compatible = "renesas,rx-sci"; /* in zephyr/dts/rx/renesas/rx26t-common.dtsi:481 */
			interrupts = < 0x54 0x1 >,
			             < 0x55 0x1 >;     /* in zephyr/dts/rx/renesas/rx26t-common.dtsi:482 */
			interrupt-names = "rxi",
			                  "txi";       /* in zephyr/dts/rx/renesas/rx26t-common.dtsi:483 */
			reg = < 0x8a0a0 0x20 >;        /* in zephyr/dts/rx/renesas/rx26t-common.dtsi:484 */
			clocks = < &pclkb 0x1 0x1a >;  /* in zephyr/dts/rx/renesas/rx26t-common.dtsi:485 */
			status = "disabled";           /* in zephyr/dts/rx/renesas/rx26t-common.dtsi:486 */
			channel = < 0x5 >;             /* in zephyr/dts/rx/renesas/rx26t-common.dtsi:487 */

			/* node '/soc/sci5@8a0a0/uart' defined in zephyr/dts/rx/renesas/rx26t-common.dtsi:489 */
			uart {
				compatible = "renesas,rx-uart-sci"; /* in zephyr/dts/rx/renesas/rx26t-common.dtsi:490 */
				status = "disabled";                /* in zephyr/dts/rx/renesas/rx26t-common.dtsi:491 */
			};
		};

		/* node '/soc/sci6@8a0c0' defined in zephyr/dts/rx/renesas/rx26t-common.dtsi:495 */
		sci6: sci6@8a0c0 {
			compatible = "renesas,rx-sci"; /* in zephyr/dts/rx/renesas/rx26t-common.dtsi:496 */
			interrupts = < 0x56 0x1 >,
			             < 0x57 0x1 >;     /* in zephyr/dts/rx/renesas/rx26t-common.dtsi:497 */
			interrupt-names = "rxi",
			                  "txi";       /* in zephyr/dts/rx/renesas/rx26t-common.dtsi:498 */
			reg = < 0x8a0c0 0x20 >;        /* in zephyr/dts/rx/renesas/rx26t-common.dtsi:499 */
			clocks = < &pclkb 0x1 0x19 >;  /* in zephyr/dts/rx/renesas/rx26t-common.dtsi:500 */
			status = "disabled";           /* in zephyr/dts/rx/renesas/rx26t-common.dtsi:501 */
			channel = < 0x6 >;             /* in zephyr/dts/rx/renesas/rx26t-common.dtsi:502 */

			/* node '/soc/sci6@8a0c0/uart' defined in zephyr/dts/rx/renesas/rx26t-common.dtsi:504 */
			uart {
				compatible = "renesas,rx-uart-sci"; /* in zephyr/dts/rx/renesas/rx26t-common.dtsi:505 */
				status = "disabled";                /* in zephyr/dts/rx/renesas/rx26t-common.dtsi:506 */
			};
		};

		/* node '/soc/sci12@8b300' defined in zephyr/dts/rx/renesas/rx26t-common.dtsi:510 */
		sci12: sci12@8b300 {
			compatible = "renesas,rx-sci";  /* in zephyr/dts/rx/renesas/rx26t-common.dtsi:511 */
			interrupts = < 0x74 0x1 >,
			             < 0x75 0x1 >;      /* in zephyr/dts/rx/renesas/rx26t-common.dtsi:512 */
			interrupt-names = "rxi",
			                  "txi";        /* in zephyr/dts/rx/renesas/rx26t-common.dtsi:513 */
			reg = < 0x8b300 0x20 >;         /* in zephyr/dts/rx/renesas/rx26t-common.dtsi:514 */
			clocks = < &pclkb 0x1 0x4 >;    /* in zephyr/dts/rx/renesas/rx26t-common.dtsi:515 */
			channel = < 0xc >;              /* in zephyr/dts/rx/renesas/rx26t-common.dtsi:517 */
			pinctrl-0 = < &sci12_default >; /* in zephyr/boards/renesas/mcb_rx26t/mcb_rx26t.dts:83 */
			pinctrl-names = "default";      /* in zephyr/boards/renesas/mcb_rx26t/mcb_rx26t.dts:84 */
			status = "okay";                /* in zephyr/boards/renesas/mcb_rx26t/mcb_rx26t.dts:85 */

			/* node '/soc/sci12@8b300/uart' defined in zephyr/dts/rx/renesas/rx26t-common.dtsi:519 */
			uart12: uart {
				compatible = "renesas,rx-uart-sci"; /* in zephyr/dts/rx/renesas/rx26t-common.dtsi:520 */
				current-speed = < 0x1c200 >;        /* in zephyr/boards/renesas/mcb_rx26t/mcb_rx26t.dts:88 */
				status = "okay";                    /* in zephyr/boards/renesas/mcb_rx26t/mcb_rx26t.dts:89 */
			};
		};

		/* node '/soc/timer@88000' defined in zephyr/dts/rx/renesas/rx26t-common.dtsi:525 */
		cmt: timer@88000 {
			compatible = "renesas,rx-timer-cmt-start-control"; /* in zephyr/dts/rx/renesas/rx26t-common.dtsi:526 */
			#address-cells = < 0x1 >;                          /* in zephyr/dts/rx/renesas/rx26t-common.dtsi:527 */
			#size-cells = < 0x1 >;                             /* in zephyr/dts/rx/renesas/rx26t-common.dtsi:528 */
			clocks = < &pclkb 0x0 0xf >;                       /* in zephyr/dts/rx/renesas/rx26t-common.dtsi:529 */
			reg = < 0x88000 0x2 >;                             /* in zephyr/dts/rx/renesas/rx26t-common.dtsi:530 */
			reg-names = "CMSTR0";                              /* in zephyr/dts/rx/renesas/rx26t-common.dtsi:531 */
			clock-frequency = < 0x3938700 >;                   /* in zephyr/boards/renesas/mcb_rx26t/mcb_rx26t.dts:70 */
			status = "okay";                                   /* in zephyr/boards/renesas/mcb_rx26t/mcb_rx26t.dts:71 */

			/* node '/soc/timer@88000/timer@88002' defined in zephyr/dts/rx/renesas/rx26t-common.dtsi:534 */
			cmt0: timer@88002 {
				compatible = "renesas,rx-timer-cmt"; /* in zephyr/dts/rx/renesas/rx26t-common.dtsi:535 */
				#address-cells = < 0x1 >;            /* in zephyr/dts/rx/renesas/rx26t-common.dtsi:536 */
				#size-cells = < 0x1 >;               /* in zephyr/dts/rx/renesas/rx26t-common.dtsi:537 */
				reg = < 0x88002 0x2 >,
				      < 0x88004 0x2 >,
				      < 0x88006 0x2 >;               /* in zephyr/dts/rx/renesas/rx26t-common.dtsi:538 */
				reg-names = "CMCR",
				            "CMCNT",
				            "CMCOR";                 /* in zephyr/dts/rx/renesas/rx26t-common.dtsi:541 */
				interrupts = < 0x1c 0x1 >;           /* in zephyr/dts/rx/renesas/rx26t-common.dtsi:542 */
				interrupt-names = "cmi";             /* in zephyr/dts/rx/renesas/rx26t-common.dtsi:543 */
				status = "okay";                     /* in zephyr/dts/rx/renesas/rx26t-common.dtsi:544 */
			};

			/* node '/soc/timer@88000/timer@88008' defined in zephyr/dts/rx/renesas/rx26t-common.dtsi:547 */
			cmt1: timer@88008 {
				compatible = "renesas,rx-timer-cmt"; /* in zephyr/dts/rx/renesas/rx26t-common.dtsi:548 */
				reg = < 0x88008 0x2 >,
				      < 0x8800a 0x2 >,
				      < 0x8800c 0x2 >;               /* in zephyr/dts/rx/renesas/rx26t-common.dtsi:549 */
				reg-names = "CMCR",
				            "CMCNT",
				            "CMCOR";                 /* in zephyr/dts/rx/renesas/rx26t-common.dtsi:552 */
				interrupts = < 0x1d 0x1 >;           /* in zephyr/dts/rx/renesas/rx26t-common.dtsi:553 */
				interrupt-names = "cmi";             /* in zephyr/dts/rx/renesas/rx26t-common.dtsi:554 */
				status = "okay";                     /* in zephyr/dts/rx/renesas/rx26t-common.dtsi:555 */
			};
		};

		/* node '/soc/ofsm@120040' defined in zephyr/dts/rx/renesas/rx26t-common.dtsi:559 */
		ofsm: ofsm@120040 {
			compatible = "zephyr,memory-region"; /* in zephyr/dts/rx/renesas/rx26t-common.dtsi:560 */
			reg = < 0x120040 0xbf >;             /* in zephyr/dts/rx/renesas/rx26t-common.dtsi:561 */
			zephyr,memory-region = "OFSM";       /* in zephyr/dts/rx/renesas/rx26t-common.dtsi:562 */
			status = "okay";                     /* in zephyr/dts/rx/renesas/rx26t-common.dtsi:563 */
		};

		/* node '/soc/memory@0' defined in zephyr/dts/rx/renesas/r5f526tfddfp.dtsi:157 */
		sram0: memory@0 {
			device_type = "memory";   /* in zephyr/dts/rx/renesas/r5f526tfddfp.dtsi:158 */
			compatible = "mmio-sram"; /* in zephyr/dts/rx/renesas/r5f526tfddfp.dtsi:159 */
			reg = < 0x0 0x10000 >;    /* in zephyr/dts/rx/renesas/r5f526tfddfp.dtsi:160 */
		};

		/* node '/soc/flash-controller@7e0000' defined in zephyr/dts/rx/renesas/r5f526tfddfp.dtsi:163 */
		flash: flash-controller@7e0000 {
			#address-cells = < 0x1 >;        /* in zephyr/dts/rx/renesas/r5f526tfddfp.dtsi:164 */
			#size-cells = < 0x1 >;           /* in zephyr/dts/rx/renesas/r5f526tfddfp.dtsi:165 */
			compatible = "renesas,rx-flash"; /* in zephyr/dts/rx/renesas/r5f526tfddfp.dtsi:166 */
			reg = < 0x7e0000 0x1000 >;       /* in zephyr/dts/rx/renesas/r5f526tfddfp.dtsi:167 */

			/* node '/soc/flash-controller@7e0000/flash@fff80000' defined in zephyr/dts/rx/renesas/r5f526tfddfp.dtsi:169 */
			code_flash: flash@fff80000 {
				compatible = "renesas,rx-nv-flash"; /* in zephyr/dts/rx/renesas/r5f526tfddfp.dtsi:170 */
				reg = < 0xfff80000 0x80000 >;       /* in zephyr/dts/rx/renesas/r5f526tfddfp.dtsi:171 */
			};

			/* node '/soc/flash-controller@7e0000/flash@100000' defined in zephyr/dts/rx/renesas/r5f526tfddfp.dtsi:174 */
			data_flash: flash@100000 {
				compatible = "renesas,rx-nv-flash"; /* in zephyr/dts/rx/renesas/r5f526tfddfp.dtsi:175 */
				reg = < 0x100000 0x4000 >;          /* in zephyr/dts/rx/renesas/r5f526tfddfp.dtsi:176 */
			};
		};
	};

	/* node '/clocks' defined in zephyr/dts/rx/renesas/r5f526tfddfp.dtsi:12 */
	clocks: clocks {
		#address-cells = < 0x1 >; /* in zephyr/dts/rx/renesas/r5f526tfddfp.dtsi:13 */
		#size-cells = < 0x1 >;    /* in zephyr/dts/rx/renesas/r5f526tfddfp.dtsi:14 */

		/* node '/clocks/clock-main-osc' defined in zephyr/dts/rx/renesas/r5f526tfddfp.dtsi:16 */
		xtal: clock-main-osc {
			compatible = "renesas,rx-cgc-root-clock"; /* in zephyr/dts/rx/renesas/r5f526tfddfp.dtsi:17 */
			stabilization-time = < 0x4 >;             /* in zephyr/dts/rx/renesas/r5f526tfddfp.dtsi:20 */
			clock-frequency = < 0x989680 >;           /* in zephyr/boards/renesas/mcb_rx26t/mcb_rx26t.dts:57 */
			mosel = < 0x0 >;                          /* in zephyr/boards/renesas/mcb_rx26t/mcb_rx26t.dts:58 */
			#clock-cells = < 0x0 >;                   /* in zephyr/boards/renesas/mcb_rx26t/mcb_rx26t.dts:59 */
			status = "okay";                          /* in zephyr/boards/renesas/mcb_rx26t/mcb_rx26t.dts:60 */
			phandle = < 0x12 >;                       /* in zephyr/dts/rx/renesas/r5f526tfddfp.dtsi:50 */
		};

		/* node '/clocks/clock-hoco' defined in zephyr/dts/rx/renesas/r5f526tfddfp.dtsi:25 */
		hoco: clock-hoco {
			compatible = "renesas,rx-cgc-root-clock"; /* in zephyr/dts/rx/renesas/r5f526tfddfp.dtsi:26 */
			clock-frequency = < 0xf42400 >;           /* in zephyr/dts/rx/renesas/r5f526tfddfp.dtsi:27 */
			#clock-cells = < 0x0 >;                   /* in zephyr/dts/rx/renesas/r5f526tfddfp.dtsi:28 */
			status = "okay";                          /* in zephyr/dts/rx/renesas/r5f526tfddfp.dtsi:29 */
			phandle = < 0x15 >;                       /* in zephyr/dts/rx/renesas/r5f526tfddfp.dtsi:136 */
		};

		/* node '/clocks/clock-loco' defined in zephyr/dts/rx/renesas/r5f526tfddfp.dtsi:32 */
		loco: clock-loco {
			compatible = "renesas,rx-cgc-root-clock"; /* in zephyr/dts/rx/renesas/r5f526tfddfp.dtsi:33 */
			clock-frequency = < 0x3a980 >;            /* in zephyr/dts/rx/renesas/r5f526tfddfp.dtsi:34 */
			#clock-cells = < 0x0 >;                   /* in zephyr/dts/rx/renesas/r5f526tfddfp.dtsi:35 */
			status = "okay";                          /* in zephyr/dts/rx/renesas/r5f526tfddfp.dtsi:36 */
			phandle = < 0x14 >;                       /* in zephyr/dts/rx/renesas/r5f526tfddfp.dtsi:122 */
		};

		/* node '/clocks/clock-iwdt-low-speed' defined in zephyr/dts/rx/renesas/r5f526tfddfp.dtsi:39 */
		iwdtlsclk: clock-iwdt-low-speed {
			compatible = "renesas,rx-cgc-root-clock"; /* in zephyr/dts/rx/renesas/r5f526tfddfp.dtsi:40 */
			clock-frequency = < 0x1d4c0 >;            /* in zephyr/dts/rx/renesas/r5f526tfddfp.dtsi:41 */
			#clock-cells = < 0x0 >;                   /* in zephyr/dts/rx/renesas/r5f526tfddfp.dtsi:42 */
			status = "disabled";                      /* in zephyr/dts/rx/renesas/r5f526tfddfp.dtsi:43 */
			phandle = < 0x16 >;                       /* in zephyr/dts/rx/renesas/r5f526tfddfp.dtsi:143 */
		};

		/* node '/clocks/pll' defined in zephyr/dts/rx/renesas/r5f526tfddfp.dtsi:46 */
		pll: pll {
			compatible = "renesas,rx-cgc-pll"; /* in zephyr/dts/rx/renesas/r5f526tfddfp.dtsi:47 */
			#clock-cells = < 0x0 >;            /* in zephyr/dts/rx/renesas/r5f526tfddfp.dtsi:48 */
			clocks = < &xtal >;                /* in zephyr/dts/rx/renesas/r5f526tfddfp.dtsi:50 */
			div = < 0x1 >;                     /* in zephyr/boards/renesas/mcb_rx26t/mcb_rx26t.dts:64 */
			mul = < 0x2f >;                    /* in zephyr/boards/renesas/mcb_rx26t/mcb_rx26t.dts:65 */
			status = "okay";                   /* in zephyr/boards/renesas/mcb_rx26t/mcb_rx26t.dts:66 */
			phandle = < 0x13 >;                /* in zephyr/dts/rx/renesas/r5f526tfddfp.dtsi:67 */
		};

		/* node '/clocks/clock-canfdm' defined in zephyr/dts/rx/renesas/r5f526tfddfp.dtsi:55 */
		canfdmclk: clock-canfdm {
			compatible = "renesas,rx-cgc-root-clock"; /* in zephyr/dts/rx/renesas/r5f526tfddfp.dtsi:56 */
			clock-frequency = < 0x16e3600 >;          /* in zephyr/dts/rx/renesas/r5f526tfddfp.dtsi:57 */
			#clock-cells = < 0x0 >;                   /* in zephyr/dts/rx/renesas/r5f526tfddfp.dtsi:58 */
			status = "okay";                          /* in zephyr/dts/rx/renesas/r5f526tfddfp.dtsi:59 */
		};

		/* node '/clocks/pclkblock@80010' defined in zephyr/dts/rx/renesas/r5f526tfddfp.dtsi:62 */
		pclkblock: pclkblock@80010 {
			compatible = "renesas,rx-cgc-pclk-block"; /* in zephyr/dts/rx/renesas/r5f526tfddfp.dtsi:63 */
			reg = < 0x80010 0x4 >,
			      < 0x80014 0x4 >,
			      < 0x80018 0x4 >,
			      < 0x8001c 0x4 >;                    /* in zephyr/dts/rx/renesas/r5f526tfddfp.dtsi:64 */
			reg-names = "MSTPA",
			            "MSTPB",
			            "MSTPC",
			            "MSTPD";                      /* in zephyr/dts/rx/renesas/r5f526tfddfp.dtsi:65 */
			#clock-cells = < 0x0 >;                   /* in zephyr/dts/rx/renesas/r5f526tfddfp.dtsi:66 */
			clocks = < &pll >;                        /* in zephyr/dts/rx/renesas/r5f526tfddfp.dtsi:67 */
			status = "okay";                          /* in zephyr/dts/rx/renesas/r5f526tfddfp.dtsi:68 */

			/* node '/clocks/pclkblock@80010/iclk' defined in zephyr/dts/rx/renesas/r5f526tfddfp.dtsi:70 */
			iclk: iclk {
				compatible = "renesas,rx-cgc-pclk"; /* in zephyr/dts/rx/renesas/r5f526tfddfp.dtsi:71 */
				div = < 0x2 >;                      /* in zephyr/dts/rx/renesas/r5f526tfddfp.dtsi:72 */
				#clock-cells = < 0x2 >;             /* in zephyr/dts/rx/renesas/r5f526tfddfp.dtsi:73 */
				status = "okay";                    /* in zephyr/dts/rx/renesas/r5f526tfddfp.dtsi:74 */
			};

			/* node '/clocks/pclkblock@80010/fclk' defined in zephyr/dts/rx/renesas/r5f526tfddfp.dtsi:77 */
			fclk: fclk {
				compatible = "renesas,rx-cgc-pclk"; /* in zephyr/dts/rx/renesas/r5f526tfddfp.dtsi:78 */
				div = < 0x4 >;                      /* in zephyr/dts/rx/renesas/r5f526tfddfp.dtsi:79 */
				#clock-cells = < 0x2 >;             /* in zephyr/dts/rx/renesas/r5f526tfddfp.dtsi:80 */
				status = "okay";                    /* in zephyr/dts/rx/renesas/r5f526tfddfp.dtsi:81 */
			};

			/* node '/clocks/pclkblock@80010/pclka' defined in zephyr/dts/rx/renesas/r5f526tfddfp.dtsi:84 */
			pclka: pclka {
				compatible = "renesas,rx-cgc-pclk"; /* in zephyr/dts/rx/renesas/r5f526tfddfp.dtsi:85 */
				div = < 0x2 >;                      /* in zephyr/dts/rx/renesas/r5f526tfddfp.dtsi:86 */
				#clock-cells = < 0x2 >;             /* in zephyr/dts/rx/renesas/r5f526tfddfp.dtsi:87 */
				status = "okay";                    /* in zephyr/dts/rx/renesas/r5f526tfddfp.dtsi:88 */
			};

			/* node '/clocks/pclkblock@80010/pclkb' defined in zephyr/dts/rx/renesas/r5f526tfddfp.dtsi:91 */
			pclkb: pclkb {
				compatible = "renesas,rx-cgc-pclk"; /* in zephyr/dts/rx/renesas/r5f526tfddfp.dtsi:92 */
				div = < 0x4 >;                      /* in zephyr/dts/rx/renesas/r5f526tfddfp.dtsi:93 */
				#clock-cells = < 0x2 >;             /* in zephyr/dts/rx/renesas/r5f526tfddfp.dtsi:94 */
				status = "okay";                    /* in zephyr/dts/rx/renesas/r5f526tfddfp.dtsi:95 */
				phandle = < 0x10 >;                 /* in zephyr/dts/rx/renesas/rx26t-common.dtsi:470 */
			};

			/* node '/clocks/pclkblock@80010/pclkc' defined in zephyr/dts/rx/renesas/r5f526tfddfp.dtsi:98 */
			pclkc: pclkc {
				compatible = "renesas,rx-cgc-pclk"; /* in zephyr/dts/rx/renesas/r5f526tfddfp.dtsi:99 */
				div = < 0x2 >;                      /* in zephyr/dts/rx/renesas/r5f526tfddfp.dtsi:100 */
				#clock-cells = < 0x2 >;             /* in zephyr/dts/rx/renesas/r5f526tfddfp.dtsi:101 */
				status = "okay";                    /* in zephyr/dts/rx/renesas/r5f526tfddfp.dtsi:102 */
			};

			/* node '/clocks/pclkblock@80010/pclkd' defined in zephyr/dts/rx/renesas/r5f526tfddfp.dtsi:105 */
			pclkd: pclkd {
				compatible = "renesas,rx-cgc-pclk"; /* in zephyr/dts/rx/renesas/r5f526tfddfp.dtsi:106 */
				div = < 0x4 >;                      /* in zephyr/dts/rx/renesas/r5f526tfddfp.dtsi:107 */
				#clock-cells = < 0x2 >;             /* in zephyr/dts/rx/renesas/r5f526tfddfp.dtsi:108 */
				status = "okay";                    /* in zephyr/dts/rx/renesas/r5f526tfddfp.dtsi:109 */
			};

			/* node '/clocks/pclkblock@80010/clock-canfd' defined in zephyr/dts/rx/renesas/r5f526tfddfp.dtsi:112 */
			canfdclk: clock-canfd {
				compatible = "renesas,rx-cgc-pclk"; /* in zephyr/dts/rx/renesas/r5f526tfddfp.dtsi:113 */
				div = < 0x2 >;                      /* in zephyr/dts/rx/renesas/r5f526tfddfp.dtsi:114 */
				#clock-cells = < 0x2 >;             /* in zephyr/dts/rx/renesas/r5f526tfddfp.dtsi:115 */
				status = "okay";                    /* in zephyr/dts/rx/renesas/r5f526tfddfp.dtsi:116 */
			};
		};

		/* node '/clocks/caclclk' defined in zephyr/dts/rx/renesas/r5f526tfddfp.dtsi:120 */
		caclclk: caclclk {
			compatible = "renesas,rx-cgc-pclk"; /* in zephyr/dts/rx/renesas/r5f526tfddfp.dtsi:121 */
			clocks = < &loco >;                 /* in zephyr/dts/rx/renesas/r5f526tfddfp.dtsi:122 */
			#clock-cells = < 0x2 >;             /* in zephyr/dts/rx/renesas/r5f526tfddfp.dtsi:123 */
			status = "disabled";                /* in zephyr/dts/rx/renesas/r5f526tfddfp.dtsi:124 */
		};

		/* node '/clocks/cacmclk' defined in zephyr/dts/rx/renesas/r5f526tfddfp.dtsi:127 */
		cacmclk: cacmclk {
			compatible = "renesas,rx-cgc-pclk"; /* in zephyr/dts/rx/renesas/r5f526tfddfp.dtsi:128 */
			clocks = < &xtal >;                 /* in zephyr/dts/rx/renesas/r5f526tfddfp.dtsi:129 */
			#clock-cells = < 0x2 >;             /* in zephyr/dts/rx/renesas/r5f526tfddfp.dtsi:130 */
			status = "disabled";                /* in zephyr/dts/rx/renesas/r5f526tfddfp.dtsi:131 */
		};

		/* node '/clocks/cachclk' defined in zephyr/dts/rx/renesas/r5f526tfddfp.dtsi:134 */
		cachclk: cachclk {
			compatible = "renesas,rx-cgc-pclk"; /* in zephyr/dts/rx/renesas/r5f526tfddfp.dtsi:135 */
			clocks = < &hoco >;                 /* in zephyr/dts/rx/renesas/r5f526tfddfp.dtsi:136 */
			#clock-cells = < 0x2 >;             /* in zephyr/dts/rx/renesas/r5f526tfddfp.dtsi:137 */
			status = "disabled";                /* in zephyr/dts/rx/renesas/r5f526tfddfp.dtsi:138 */
		};

		/* node '/clocks/caciclk' defined in zephyr/dts/rx/renesas/r5f526tfddfp.dtsi:141 */
		caciclk: caciclk {
			compatible = "renesas,rx-cgc-pclk"; /* in zephyr/dts/rx/renesas/r5f526tfddfp.dtsi:142 */
			clocks = < &iwdtlsclk >;            /* in zephyr/dts/rx/renesas/r5f526tfddfp.dtsi:143 */
			#clock-cells = < 0x2 >;             /* in zephyr/dts/rx/renesas/r5f526tfddfp.dtsi:144 */
			status = "disabled";                /* in zephyr/dts/rx/renesas/r5f526tfddfp.dtsi:145 */
		};

		/* node '/clocks/iwdtclk' defined in zephyr/dts/rx/renesas/r5f526tfddfp.dtsi:148 */
		iwdtclk: iwdtclk {
			compatible = "renesas,rx-cgc-pclk"; /* in zephyr/dts/rx/renesas/r5f526tfddfp.dtsi:149 */
			clocks = < &iwdtlsclk >;            /* in zephyr/dts/rx/renesas/r5f526tfddfp.dtsi:150 */
			#clock-cells = < 0x2 >;             /* in zephyr/dts/rx/renesas/r5f526tfddfp.dtsi:151 */
			status = "disabled";                /* in zephyr/dts/rx/renesas/r5f526tfddfp.dtsi:152 */
		};
	};

	/* node '/chosen' defined in zephyr/boards/renesas/mcb_rx26t/mcb_rx26t.dts:17 */
	chosen {
		zephyr,sram = &sram0;        /* in zephyr/boards/renesas/mcb_rx26t/mcb_rx26t.dts:18 */
		zephyr,flash = &code_flash;  /* in zephyr/boards/renesas/mcb_rx26t/mcb_rx26t.dts:19 */
		zephyr,console = &uart12;    /* in zephyr/boards/renesas/mcb_rx26t/mcb_rx26t.dts:20 */
		zephyr,shell-uart = &uart12; /* in zephyr/boards/renesas/mcb_rx26t/mcb_rx26t.dts:21 */
	};

	/* node '/leds' defined in zephyr/boards/renesas/mcb_rx26t/mcb_rx26t.dts:24 */
	leds {
		compatible = "gpio-leds"; /* in zephyr/boards/renesas/mcb_rx26t/mcb_rx26t.dts:25 */

		/* node '/leds/led1' defined in zephyr/boards/renesas/mcb_rx26t/mcb_rx26t.dts:27 */
		led1: led1 {
			gpios = < &ioport2 0x1 0x1 >; /* in zephyr/boards/renesas/mcb_rx26t/mcb_rx26t.dts:28 */
			label = "LED1";               /* in zephyr/boards/renesas/mcb_rx26t/mcb_rx26t.dts:29 */
		};

		/* node '/leds/led2' defined in zephyr/boards/renesas/mcb_rx26t/mcb_rx26t.dts:32 */
		led2: led2 {
			gpios = < &ioport2 0x0 0x1 >; /* in zephyr/boards/renesas/mcb_rx26t/mcb_rx26t.dts:33 */
			label = "LED2";               /* in zephyr/boards/renesas/mcb_rx26t/mcb_rx26t.dts:34 */
		};

		/* node '/leds/led3' defined in zephyr/boards/renesas/mcb_rx26t/mcb_rx26t.dts:37 */
		led3: led3 {
			gpios = < &ioport6 0x5 0x1 >; /* in zephyr/boards/renesas/mcb_rx26t/mcb_rx26t.dts:38 */
			label = "LED3";               /* in zephyr/boards/renesas/mcb_rx26t/mcb_rx26t.dts:39 */
		};

		/* node '/leds/led4' defined in zephyr/boards/renesas/mcb_rx26t/mcb_rx26t.dts:42 */
		led4: led4 {
			gpios = < &ioport6 0x4 0x1 >; /* in zephyr/boards/renesas/mcb_rx26t/mcb_rx26t.dts:43 */
			label = "LED3";               /* in zephyr/boards/renesas/mcb_rx26t/mcb_rx26t.dts:44 */
		};
	};

	/* node '/aliases' defined in zephyr/boards/renesas/mcb_rx26t/mcb_rx26t.dts:48 */
	aliases {
		led0 = &led1; /* in zephyr/boards/renesas/mcb_rx26t/mcb_rx26t.dts:49 */
		led1 = &led2; /* in zephyr/boards/renesas/mcb_rx26t/mcb_rx26t.dts:50 */
		led2 = &led3; /* in zephyr/boards/renesas/mcb_rx26t/mcb_rx26t.dts:51 */
		led3 = &led4; /* in zephyr/boards/renesas/mcb_rx26t/mcb_rx26t.dts:52 */
	};
};
